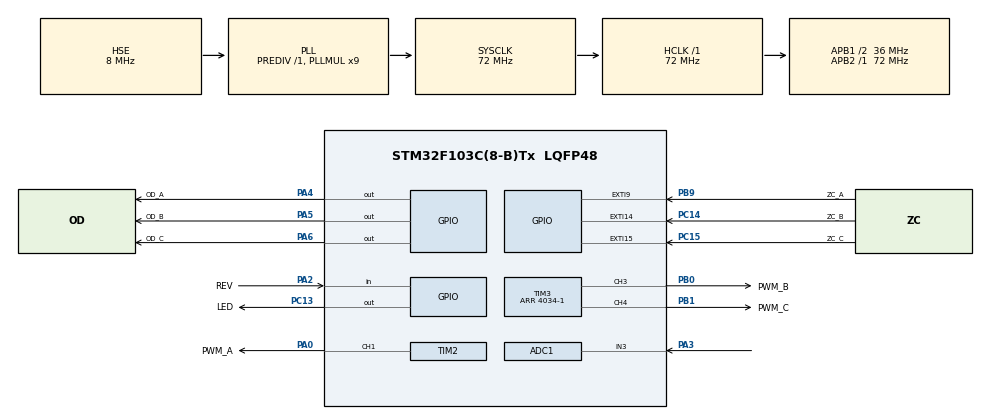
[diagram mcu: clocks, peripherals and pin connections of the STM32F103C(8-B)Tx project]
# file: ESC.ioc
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ADC1.Channel-0\#ChannelRegularConversion=ADC_CHANNEL_3
ADC1.ContinuousConvMode=DISABLE
ADC1.NbrOfConversion=1
ADC1.NbrOfConversionFlag=1
ADC1.Rank-0\#ChannelRegularConversion=1
ADC1.SamplingTime-0\#ChannelRegularConversion=ADC_SAMPLETIME_1CYCLE_5
ADC1.master=1
Dma.ADC1.0.Direction=DMA_PERIPH_TO_MEMORY
Dma.ADC1.0.Instance=DMA1_Channel1
Dma.ADC1.0.MemDataAlignment=DMA_MDATAALIGN_HALFWORD
Dma.ADC1.0.MemInc=DMA_MINC_ENABLE
Dma.ADC1.0.Mode=DMA_NORMAL
Dma.ADC1.0.PeriphDataAlignment=DMA_PDATAALIGN_HALFWORD
Dma.ADC1.0.PeriphInc=DMA_PINC_DISABLE
Dma.ADC1.0.Priority=DMA_PRIORITY_VERY_HIGH
Dma.Request0=ADC1
Dma.Request1=TIM3_CH3
Dma.Request2=TIM3_CH4/UP
Dma.Request3=TIM2_CH1
Dma.TIM2_CH1.3.Direction=DMA_MEMORY_TO_PERIPH
Dma.TIM2_CH1.3.Instance=DMA1_Channel5
Dma.TIM2_CH1.3.MemDataAlignment=DMA_MDATAALIGN_HALFWORD
Dma.TIM2_CH1.3.MemInc=DMA_MINC_ENABLE
Dma.TIM2_CH1.3.Mode=DMA_CIRCULAR
Dma.TIM2_CH1.3.PeriphDataAlignment=DMA_PDATAALIGN_HALFWORD
Dma.TIM2_CH1.3.PeriphInc=DMA_PINC_DISABLE
Dma.TIM2_CH1.3.Priority=DMA_PRIORITY_VERY_HIGH
Dma.TIM3_CH3.1.Direction=DMA_MEMORY_TO_PERIPH
Dma.TIM3_CH3.1.Instance=DMA1_Channel2
Dma.TIM3_CH3.1.MemDataAlignment=DMA_MDATAALIGN_HALFWORD
Dma.TIM3_CH3.1.MemInc=DMA_MINC_ENABLE
Dma.TIM3_CH3.1.Mode=DMA_CIRCULAR
Dma.TIM3_CH3.1.PeriphDataAlignment=DMA_PDATAALIGN_HALFWORD
Dma.TIM3_CH3.1.PeriphInc=DMA_PINC_DISABLE
Dma.TIM3_CH3.1.Priority=DMA_PRIORITY_VERY_HIGH
Dma.TIM3_CH4/UP.2.Direction=DMA_MEMORY_TO_PERIPH
Dma.TIM3_CH4/UP.2.Instance=DMA1_Channel3
Dma.TIM3_CH4/UP.2.MemDataAlignment=DMA_MDATAALIGN_HALFWORD
Dma.TIM3_CH4/UP.2.MemInc=DMA_MINC_ENABLE
Dma.TIM3_CH4/UP.2.Mode=DMA_CIRCULAR
Dma.TIM3_CH4/UP.2.PeriphDataAlignment=DMA_PDATAALIGN_HALFWORD
Dma.TIM3_CH4/UP.2.PeriphInc=DMA_PINC_DISABLE
Dma.TIM3_CH4/UP.2.Priority=DMA_PRIORITY_VERY_HIGH
Mcu.Family=STM32F1
Mcu.Name=STM32F103C(8-B)Tx
Mcu.Package=LQFP48
NVIC.DMA1_Channel1_IRQn=true\:0\:0\:false\:false\:true\:false\:true\:true
NVIC.EXTI15_10_IRQn=true\:1\:0\:true\:false\:true\:true\:true\:true
NVIC.EXTI9_5_IRQn=true\:1\:0\:true\:false\:true\:true\:true\:true
NVIC.PriorityGroup=NVIC_PRIORITYGROUP_4
NVIC.TIM4_IRQn=true\:0\:0\:false\:false\:true\:true\:true\:true
PA0-WKUP.GPIO_Label=PWM_A
PA0-WKUP.Signal=S_TIM2_CH1_ETR
PA13.Mode=Serial_Wire
PA13.Signal=SYS_JTMS-SWDIO
PA14.Mode=Serial_Wire
PA14.Signal=SYS_JTCK-SWCLK
PA2.GPIO_Label=REV
PA2.GPIO_PuPd=GPIO_PULLDOWN
PA2.Signal=GPIO_Input
PA3.Signal=ADCx_IN3
PA4.GPIO_Label=OD_A
PA4.GPIO_PuPd=GPIO_PULLDOWN
PA4.Signal=GPIO_Output
PA5.GPIO_Label=OD_B
PA5.GPIO_PuPd=GPIO_PULLDOWN
PA5.Signal=GPIO_Output
PA6.GPIO_Label=OD_C
PA6.GPIO_PuPd=GPIO_PULLDOWN
PA6.Signal=GPIO_Output
PB0.GPIO_Label=PWM_B
PB0.Signal=S_TIM3_CH3
PB1.GPIO_Label=PWM_C
PB1.Signal=S_TIM3_CH4
PB9.GPIO_Label=ZC_A
PB9.GPIO_ModeDefaultEXTI=GPIO_MODE_IT_FALLING
PB9.GPIO_PuPd=GPIO_PULLUP
PB9.Signal=GPXTI9
PC13-TAMPER-RTC.GPIO_Label=LED
PC13-TAMPER-RTC.Signal=GPIO_Output
PC14-OSC32_IN.GPIO_Label=ZC_B
PC14-OSC32_IN.GPIO_ModeDefaultEXTI=GPIO_MODE_IT_FALLING
PC14-OSC32_IN.GPIO_PuPd=GPIO_PULLUP
PC14-OSC32_IN.Signal=GPXTI14
PC15-OSC32_OUT.GPIO_Label=ZC_C
PC15-OSC32_OUT.GPIO_ModeDefaultEXTI=GPIO_MODE_IT_FALLING
PC15-OSC32_OUT.GPIO_PuPd=GPIO_PULLUP
PC15-OSC32_OUT.Signal=GPXTI15
PD0-OSC_IN.Mode=HSE-External-Oscillator
PD0-OSC_IN.Signal=RCC_OSC_IN
PD1-OSC_OUT.Mode=HSE-External-Oscillator
PD1-OSC_OUT.Signal=RCC_OSC_OUT
ProjectManager.HeapSize=0x200
ProjectManager.StackSize=0x400
ProjectManager.TargetToolchain=STM32CubeIDE
RCC.ADCPresc=RCC_ADCPCLK2_DIV6
RCC.AHBFreq_Value=72000000
RCC.APB1CLKDivider=RCC_HCLK_DIV2
RCC.APB1Freq_Value=36000000
RCC.APB1TimFreq_Value=72000000
RCC.APB2Freq_Value=72000000
RCC.APB2TimFreq_Value=72000000
RCC.HCLKFreq_Value=72000000
RCC.PLLMUL=RCC_PLL_MUL9
RCC.PLLSourceVirtual=RCC_PLLSOURCE_HSE
RCC.SYSCLKFreq_VALUE=72000000
RCC.SYSCLKSource=RCC_SYSCLKSOURCE_PLLCLK
RCC.USBFreq_Value=72000000
SH.ADCx_IN3.0=ADC1_IN3,IN3
SH.S_TIM2_CH1_ETR.0=TIM2_CH1,PWM Generation1 CH1
SH.S_TIM3_CH3.0=TIM3_CH3,PWM Generation3 CH3
SH.S_TIM3_CH4.0=TIM3_CH4,PWM Generation4 CH4
TIM2.Channel-PWM\ Generation1\ CH1=TIM_CHANNEL_1
TIM2.CounterMode=TIM_COUNTERMODE_CENTERALIGNED2
TIM2.Period=4034-1
TIM3.Channel-PWM\ Generation3\ CH3=TIM_CHANNEL_3
TIM3.Channel-PWM\ Generation4\ CH4=TIM_CHANNEL_4
TIM3.CounterMode=TIM_COUNTERMODE_CENTERALIGNED2
TIM3.Period=4034-1
TIM4.Channel-Output\ Compare1\ No\ Output=TIM_CHANNEL_1
TIM4.Period=300
TIM4.Prescaler=64000
VP_TIM1_VS_ClockSourceINT.Mode=Internal
VP_TIM4_VS_no_output1.Mode=Output Compare1 No Output
board=custom

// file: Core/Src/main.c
/* USER CODE BEGIN Header */
/**
  ******************************************************************************
  * @file           : main.c
  * @brief          : Main program body
  ******************************************************************************
  * @attention
  *
  * Copyright (c) 2024 STMicroelectronics.
  * All rights reserved.
  *
  * This software is licensed under terms that can be found in the LICENSE file
  * in the root directory of this software component.
  * If no LICENSE file comes with this software, it is provided AS-IS.
  *
  ******************************************************************************
  */
/* USER CODE END Header */
#include "main.h"

ADC_HandleTypeDef hadc1;
DMA_HandleTypeDef hdma_adc1;

TIM_HandleTypeDef htim1;
TIM_HandleTypeDef htim2;
TIM_HandleTypeDef htim3;
TIM_HandleTypeDef htim4;
DMA_HandleTypeDef hdma_tim2_ch1;
DMA_HandleTypeDef hdma_tim3_ch3;
DMA_HandleTypeDef hdma_tim3_ch4_up;

void SystemClock_Config(void);
static void MX_GPIO_Init(void);
static void MX_DMA_Init(void);
static void MX_TIM1_Init(void);
static void MX_TIM3_Init(void);
static void MX_ADC1_Init(void);
static void MX_TIM2_Init(void);
static void MX_TIM4_Init(void);

int main(void)
{

  /* MCU Configuration--------------------------------------------------------*/

  /* Reset of all peripherals, Initializes the Flash interface and the Systick. */
  HAL_Init();

  /* Configure the system clock */
  SystemClock_Config();

  /* Initialize all configured peripherals */
  MX_GPIO_Init();
  MX_DMA_Init();
  MX_TIM1_Init();
  MX_TIM3_Init();
  MX_ADC1_Init();
  MX_TIM2_Init();
  MX_TIM4_Init();

  /* Infinite loop */
  /* USER CODE BEGIN WHILE */

  maincpp();
  while (1)
  {

    /* USER CODE END WHILE */

    /* USER CODE BEGIN 3 */
  }
  return 0;
  /* USER CODE END 3 */
}

void SystemClock_Config(void)
{
  RCC_OscInitTypeDef RCC_OscInitStruct = {0};
  RCC_ClkInitTypeDef RCC_ClkInitStruct = {0};
  RCC_PeriphCLKInitTypeDef PeriphClkInit = {0};

  /** Initializes the RCC Oscillators according to the specified parameters
  * in the RCC_OscInitTypeDef structure.
  */
  RCC_OscInitStruct.OscillatorType = RCC_OSCILLATORTYPE_HSE;
  RCC_OscInitStruct.HSEState = RCC_HSE_ON;
  RCC_OscInitStruct.HSEPredivValue = RCC_HSE_PREDIV_DIV1;
  RCC_OscInitStruct.HSIState = RCC_HSI_ON;
  RCC_OscInitStruct.PLL.PLLState = RCC_PLL_ON;
  RCC_OscInitStruct.PLL.PLLSource = RCC_PLLSOURCE_HSE;
  RCC_OscInitStruct.PLL.PLLMUL = RCC_PLL_MUL9;
  if (HAL_RCC_OscConfig(&RCC_OscInitStruct) != HAL_OK)
  {
    Error_Handler();
  }

  /** Initializes the CPU, AHB and APB buses clocks
  */
  RCC_ClkInitStruct.ClockType = RCC_CLOCKTYPE_HCLK|RCC_CLOCKTYPE_SYSCLK
                              |RCC_CLOCKTYPE_PCLK1|RCC_CLOCKTYPE_PCLK2;
  RCC_ClkInitStruct.SYSCLKSource = RCC_SYSCLKSOURCE_PLLCLK;
  RCC_ClkInitStruct.AHBCLKDivider = RCC_SYSCLK_DIV1;
  RCC_ClkInitStruct.APB1CLKDivider = RCC_HCLK_DIV2;
  RCC_ClkInitStruct.APB2CLKDivider = RCC_HCLK_DIV1;

  if (HAL_RCC_ClockConfig(&RCC_ClkInitStruct, FLASH_LATENCY_2) != HAL_OK)
  {
    Error_Handler();
  }
  PeriphClkInit.PeriphClockSelection = RCC_PERIPHCLK_ADC;
  PeriphClkInit.AdcClockSelection = RCC_ADCPCLK2_DIV6;
  if (HAL_RCCEx_PeriphCLKConfig(&PeriphClkInit) != HAL_OK)
  {
    Error_Handler();
  }
}

static void MX_ADC1_Init(void)
{

  ADC_ChannelConfTypeDef sConfig = {0};

  /** Common config
  */
  hadc1.Instance = ADC1;
  hadc1.Init.ScanConvMode = ADC_SCAN_DISABLE;
  hadc1.Init.ContinuousConvMode = DISABLE;
  hadc1.Init.DiscontinuousConvMode = DISABLE;
  hadc1.Init.ExternalTrigConv = ADC_SOFTWARE_START;
  hadc1.Init.DataAlign = ADC_DATAALIGN_RIGHT;
  hadc1.Init.NbrOfConversion = 1;
  if (HAL_ADC_Init(&hadc1) != HAL_OK)
  {
    Error_Handler();
  }

  /** Configure Regular Channel
  */
  sConfig.Channel = ADC_CHANNEL_3;
  sConfig.Rank = ADC_REGULAR_RANK_1;
  sConfig.SamplingTime = ADC_SAMPLETIME_1CYCLE_5;
  if (HAL_ADC_ConfigChannel(&hadc1, &sConfig) != HAL_OK)
  {
    Error_Handler();
  }

}

static void MX_TIM1_Init(void)
{

  TIM_ClockConfigTypeDef sClockSourceConfig = {0};
  TIM_MasterConfigTypeDef sMasterConfig = {0};

  htim1.Instance = TIM1;
  htim1.Init.Prescaler = 0;
  htim1.Init.CounterMode = TIM_COUNTERMODE_UP;
  htim1.Init.Period = 65535;
  htim1.Init.ClockDivision = TIM_CLOCKDIVISION_DIV1;
  htim1.Init.RepetitionCounter = 0;
  htim1.Init.AutoReloadPreload = TIM_AUTORELOAD_PRELOAD_DISABLE;
  if (HAL_TIM_Base_Init(&htim1) != HAL_OK)
  {
    Error_Handler();
  }
  sClockSourceConfig.ClockSource = TIM_CLOCKSOURCE_INTERNAL;
  if (HAL_TIM_ConfigClockSource(&htim1, &sClockSourceConfig) != HAL_OK)
  {
    Error_Handler();
  }
  sMasterConfig.MasterOutputTrigger = TIM_TRGO_RESET;
  sMasterConfig.MasterSlaveMode = TIM_MASTERSLAVEMODE_DISABLE;
  if (HAL_TIMEx_MasterConfigSynchronization(&htim1, &sMasterConfig) != HAL_OK)
  {
    Error_Handler();
  }

}

static void MX_TIM2_Init(void)
{

  TIM_MasterConfigTypeDef sMasterConfig = {0};
  TIM_OC_InitTypeDef sConfigOC = {0};

  htim2.Instance = TIM2;
  htim2.Init.Prescaler = 0;
  htim2.Init.CounterMode = TIM_COUNTERMODE_CENTERALIGNED2;
  htim2.Init.Period = 4034-1;
  htim2.Init.ClockDivision = TIM_CLOCKDIVISION_DIV1;
  htim2.Init.AutoReloadPreload = TIM_AUTORELOAD_PRELOAD_DISABLE;
  if (HAL_TIM_PWM_Init(&htim2) != HAL_OK)
  {
    Error_Handler();
  }
  sMasterConfig.MasterOutputTrigger = TIM_TRGO_RESET;
  sMasterConfig.MasterSlaveMode = TIM_MASTERSLAVEMODE_DISABLE;
  if (HAL_TIMEx_MasterConfigSynchronization(&htim2, &sMasterConfig) != HAL_OK)
  {
    Error_Handler();
  }
  sConfigOC.OCMode = TIM_OCMODE_PWM1;
  sConfigOC.Pulse = 0;
  sConfigOC.OCPolarity = TIM_OCPOLARITY_HIGH;
  sConfigOC.OCFastMode = TIM_OCFAST_DISABLE;
  if (HAL_TIM_PWM_ConfigChannel(&htim2, &sConfigOC, TIM_CHANNEL_1) != HAL_OK)
  {
    Error_Handler();
  }
  HAL_TIM_MspPostInit(&htim2);

}

static void MX_TIM3_Init(void)
{

  TIM_MasterConfigTypeDef sMasterConfig = {0};
  TIM_OC_InitTypeDef sConfigOC = {0};

  htim3.Instance = TIM3;
  htim3.Init.Prescaler = 0;
  htim3.Init.CounterMode = TIM_COUNTERMODE_CENTERALIGNED2;
  htim3.Init.Period = 4034-1;
  htim3.Init.ClockDivision = TIM_CLOCKDIVISION_DIV1;
  htim3.Init.AutoReloadPreload = TIM_AUTORELOAD_PRELOAD_DISABLE;
  if (HAL_TIM_PWM_Init(&htim3) != HAL_OK)
  {
    Error_Handler();
  }
  sMasterConfig.MasterOutputTrigger = TIM_TRGO_RESET;
  sMasterConfig.MasterSlaveMode = TIM_MASTERSLAVEMODE_DISABLE;
  if (HAL_TIMEx_MasterConfigSynchronization(&htim3, &sMasterConfig) != HAL_OK)
  {
    Error_Handler();
  }
  sConfigOC.OCMode = TIM_OCMODE_PWM1;
  sConfigOC.Pulse = 0;
  sConfigOC.OCPolarity = TIM_OCPOLARITY_HIGH;
  sConfigOC.OCFastMode = TIM_OCFAST_DISABLE;
  if (HAL_TIM_PWM_ConfigChannel(&htim3, &sConfigOC, TIM_CHANNEL_3) != HAL_OK)
  {
    Error_Handler();
  }
  if (HAL_TIM_PWM_ConfigChannel(&htim3, &sConfigOC, TIM_CHANNEL_4) != HAL_OK)
  {
    Error_Handler();
  }
  HAL_TIM_MspPostInit(&htim3);

}

static void MX_TIM4_Init(void)
{

  TIM_MasterConfigTypeDef sMasterConfig = {0};
  TIM_OC_InitTypeDef sConfigOC = {0};

  htim4.Instance = TIM4;
  htim4.Init.Prescaler = 64000;
  htim4.Init.CounterMode = TIM_COUNTERMODE_UP;
  htim4.Init.Period = 300;
  htim4.Init.ClockDivision = TIM_CLOCKDIVISION_DIV1;
  htim4.Init.AutoReloadPreload = TIM_AUTORELOAD_PRELOAD_DISABLE;
  if (HAL_TIM_OC_Init(&htim4) != HAL_OK)
  {
    Error_Handler();
  }
  sMasterConfig.MasterOutputTrigger = TIM_TRGO_RESET;
  sMasterConfig.MasterSlaveMode = TIM_MASTERSLAVEMODE_DISABLE;
  if (HAL_TIMEx_MasterConfigSynchronization(&htim4, &sMasterConfig) != HAL_OK)
  {
    Error_Handler();
  }
  sConfigOC.OCMode = TIM_OCMODE_TIMING;
  sConfigOC.Pulse = 0;
  sConfigOC.OCPolarity = TIM_OCPOLARITY_HIGH;
  sConfigOC.OCFastMode = TIM_OCFAST_DISABLE;
  if (HAL_TIM_OC_ConfigChannel(&htim4, &sConfigOC, TIM_CHANNEL_1) != HAL_OK)
  {
    Error_Handler();
  }

}

static void MX_DMA_Init(void)
{

  /* DMA controller clock enable */
  __HAL_RCC_DMA1_CLK_ENABLE();

  /* DMA interrupt init */
  /* DMA1_Channel1_IRQn interrupt configuration */
  HAL_NVIC_SetPriority(DMA1_Channel1_IRQn, 0, 0);
  HAL_NVIC_EnableIRQ(DMA1_Channel1_IRQn);

}

static void MX_GPIO_Init(void)
{
  GPIO_InitTypeDef GPIO_InitStruct = {0};

  /* GPIO Ports Clock Enable */
  __HAL_RCC_GPIOC_CLK_ENABLE();
  __HAL_RCC_GPIOD_CLK_ENABLE();
  __HAL_RCC_GPIOA_CLK_ENABLE();
  __HAL_RCC_GPIOB_CLK_ENABLE();

  /*Configure GPIO pin Output Level */
  HAL_GPIO_WritePin(LED_GPIO_Port, LED_Pin, GPIO_PIN_RESET);

  /*Configure GPIO pin Output Level */
  HAL_GPIO_WritePin(GPIOA, OD_A_Pin|OD_B_Pin|OD_C_Pin, GPIO_PIN_RESET);

  /*Configure GPIO pin : LED_Pin */
  GPIO_InitStruct.Pin = LED_Pin;
  GPIO_InitStruct.Mode = GPIO_MODE_OUTPUT_PP;
  GPIO_InitStruct.Pull = GPIO_NOPULL;
  GPIO_InitStruct.Speed = GPIO_SPEED_FREQ_LOW;
  HAL_GPIO_Init(LED_GPIO_Port, &GPIO_InitStruct);

  /*Configure GPIO pins : ZC_B_Pin ZC_C_Pin */
  GPIO_InitStruct.Pin = ZC_B_Pin|ZC_C_Pin;
  GPIO_InitStruct.Mode = GPIO_MODE_IT_FALLING;
  GPIO_InitStruct.Pull = GPIO_PULLUP;
  HAL_GPIO_Init(GPIOC, &GPIO_InitStruct);

  /*Configure GPIO pin : REV_Pin */
  GPIO_InitStruct.Pin = REV_Pin;
  GPIO_InitStruct.Mode = GPIO_MODE_INPUT;
  GPIO_InitStruct.Pull = GPIO_PULLDOWN;
  HAL_GPIO_Init(REV_GPIO_Port, &GPIO_InitStruct);

  /*Configure GPIO pins : OD_A_Pin OD_B_Pin OD_C_Pin */
  GPIO_InitStruct.Pin = OD_A_Pin|OD_B_Pin|OD_C_Pin;
  GPIO_InitStruct.Mode = GPIO_MODE_OUTPUT_PP;
  GPIO_InitStruct.Pull = GPIO_PULLDOWN;
  GPIO_InitStruct.Speed = GPIO_SPEED_FREQ_LOW;
  HAL_GPIO_Init(GPIOA, &GPIO_InitStruct);

  /*Configure GPIO pin : ZC_A_Pin */
  GPIO_InitStruct.Pin = ZC_A_Pin;
  GPIO_InitStruct.Mode = GPIO_MODE_IT_FALLING;
  GPIO_InitStruct.Pull = GPIO_PULLUP;
  HAL_GPIO_Init(ZC_A_GPIO_Port, &GPIO_InitStruct);

  /* EXTI interrupt init*/
  HAL_NVIC_SetPriority(EXTI9_5_IRQn, 1, 0);
  HAL_NVIC_EnableIRQ(EXTI9_5_IRQn);

  HAL_NVIC_SetPriority(EXTI15_10_IRQn, 1, 0);
  HAL_NVIC_EnableIRQ(EXTI15_10_IRQn);

}

void Error_Handler(void)
{
  __disable_irq();
  while (1)
  {
  }
}
